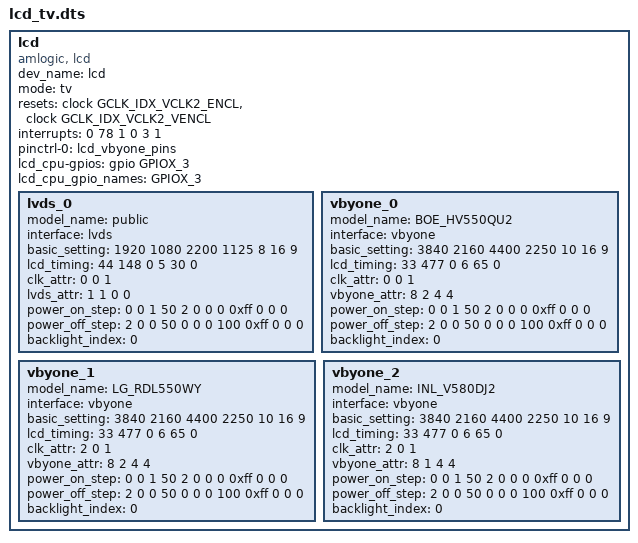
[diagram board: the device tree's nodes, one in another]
/*
 * drivers/amlogic/media/vout/lcd/lcd_tv/lcd_tv.dts
 *
 * Copyright (C) 2017 Amlogic, Inc. All rights reserved.
 *
 * This program is free software; you can redistribute it and/or modify
 * it under the terms of the GNU General Public License as published by
 * the Free Software Foundation; either version 2 of the License, or
 * (at your option) any later version.
 *
 * This program is distributed in the hope that it will be useful, but WITHOUT
 * ANY WARRANTY; without even the implied warranty of MERCHANTABILITY or
 * FITNESS FOR A PARTICULAR PURPOSE.  See the GNU General Public License for
 * more details.
 *
 */

lcd{
	compatible = "amlogic, lcd";
	dev_name = "lcd";
	mode = "tv";
	status = "okay";
	resets = <&clock GCLK_IDX_VCLK2_ENCL &clock GCLK_IDX_VCLK2_VENCL>;
	reset-names = "encl","vencl";
	interrupts = <0 78 1 0 3 1>;
	interrupt-names = "vbyone","vbyone_vsync";
	pinctrl-names = "vbyone";
	pinctrl-0 = <&lcd_vbyone_pins>;

	/* power type:(0=cpu, 1=pmu, 2=signal, 3=extern, 0xff=ending) */
	/* power index:(point gpios_index, or extern_index, 0xff=invalid) */
	/* power value:(0=output low, 1=output high, 2=input) */
	/* power delay:(unit in ms) */
	lcd_cpu-gpios = <&gpio GPIOX_3 GPIO_ACTIVE_HIGH>;
	lcd_cpu_gpio_names = "GPIOX_3";

	lvds_0{
		model_name = "public";
		interface = "lvds"; /* lcd_interface(lvds, vbyone) */
		basic_setting = <1920 1080 2200 1125 8 16 9>;
			/* h_active, v_active, h_period, v_period, lcd_bits,
			 *	screen_widht, screen_height
			 */
		lcd_timing = <44 148 0 5 30 0>;
			/* hs_width, hs_bp, hs_pol, vs_width, vs_bp, vs_pol */
		clk_attr = <0 0 1>;
			/* fr_adj_type(0=clock, 1=htotal, 2=vtotal),
			 *	clk_ss_level, clk_auto_generate
			 */
		lvds_attr = <1 1 0 0>;
			/** lvds_repack, dual_port, pn_swap, port_swap */
		power_on_step = <0 0 1 50
				2 0 0 0
				0xff 0 0 0>; /* type, index, value, delay */
		power_off_step = <2 0 0 50
				0 0 0 100
				0xff 0 0 0>; /* type, index, value, delay */
		backlight_index = <0>;
	};

	vbyone_0{
		model_name = "BOE_HV550QU2";
		interface = "vbyone"; /* lcd_interface(lvds, vbyone) */
		basic_setting = <3840 2160 4400 2250 10 16 9>;
			/* h_active, v_active, h_period, v_period, lcd_bits,
			 *	screen_widht, screen_height
			 */
		lcd_timing = <33 477 0 6 65 0>;
			/* hs_width, hs_bp, hs_pol, vs_width, vs_bp, vs_pol */
		clk_attr = <0 0 1>;
			/* fr_adj_type(0=clock, 1=htotal, 2=vtotal),
			 *	clk_ss_level, clk_auto_generate
			 */
		vbyone_attr = <8 2 4 4>;
			/** lane_count, region_num, byte_mode, color_fmt */
		power_on_step = <0 0 1 50
				2 0 0 0
				0xff 0 0 0>; /* type, index, value, delay */
		power_off_step = <2 0 0 50
				0 0 0 100
				0xff 0 0 0>; /* type, index, value, delay */
		backlight_index = <0>;
	};

	vbyone_1{
		model_name = "LG_RDL550WY";
		interface = "vbyone"; /* lcd_interface(lvds, vbyone) */
		basic_setting = <3840 2160 4400 2250 10 16 9>;
			/* h_active, v_active, h_period, v_period, lcd_bits,
			 *	screen_widht, screen_height
			 */
		lcd_timing = <33 477 0 6 65 0>;
			/* hs_width, hs_bp, hs_pol, vs_width, vs_bp, vs_pol */
		clk_attr = <2 0 1>;
			/* fr_adj_type(0=clock, 1=htotal, 2=vtotal),
			 *	clk_ss_level, clk_auto_generate
			 */
		vbyone_attr = <8 2 4 4>;
			/** lane_count, region_num, byte_mode, color_fmt */
		power_on_step = <0 0 1 50
				2 0 0 0
				0xff 0 0 0>; /* type, index, value, delay */
		power_off_step = <2 0 0 50
				0 0 0 100
				0xff 0 0 0>; /* type, index, value, delay */
		backlight_index = <0>;
	};

	vbyone_2{
		model_name = "INL_V580DJ2";
		interface = "vbyone"; /* lcd_interface(lvds, vbyone) */
		basic_setting = <3840 2160 4400 2250 10 16 9>;
			/* h_active, v_active, h_period, v_period, lcd_bits,
			 *	screen_widht, screen_height
			 */
		lcd_timing = <33 477 0 6 65 0>;
			/* hs_width, hs_bp, hs_pol, vs_width, vs_bp, vs_pol */
		clk_attr = <2 0 1>;
			/* fr_adj_type(0=clock, 1=htotal, 2=vtotal),
			 *	clk_ss_level, clk_auto_generate
			 */
		vbyone_attr = <8 1 4 4>;
			/** lane_count, region_num, byte_mode, color_fmt */
		power_on_step = <0 0 1 50
				2 0 0 0
				0xff 0 0 0>; /* type, index, value, delay */
		power_off_step = <2 0 0 50
				0 0 0 100
				0xff 0 0 0>; /* type, index, value, delay */
		backlight_index = <0>;
	};
};
